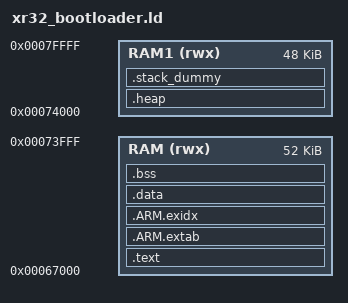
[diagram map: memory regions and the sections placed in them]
/* Linker script to configure memory regions. */
MEMORY
{
	RAM  (rwx) : ORIGIN = 0x00067000, LENGTH = 52K
	RAM1 (rwx) : ORIGIN = 0x00074000, LENGTH = 48K
}

__RAM_BASE = ORIGIN(RAM);

/* Linker script to place sections and symbol values. Should be used together
 * with other linker script that defines memory regions FLASH and RAM.
 * It references following symbols, which must be defined in code:
 *   Reset_Handler : Entry of reset handler
 *
 * It defines following symbols, which code can use without definition:
 *   __exidx_start
 *   __exidx_end
 *   __etext
 *   __data_start__
 *   __preinit_array_start
 *   __preinit_array_end
 *   __init_array_start
 *   __init_array_end
 *   __fini_array_start
 *   __fini_array_end
 *   __data_end__
 *   __bss_start__
 *   __bss_end__
 *   __end__
 *   end
 *   __HeapLimit
 *   __StackLimit
 *   __StackTop
 *   __stack
 *   _estack
 */
ENTRY(Reset_Handler)

SECTIONS
{
	.text :
	{
		. = ALIGN(4);
		__text_start__ = .;

		KEEP(*(.isr_vector))
		KEEP(*(.text.Reset_Handler))
		KEEP(*(.cpu_text))
		*(.text*)
		KEEP(*(.init))
		KEEP(*(.fini))

		/* .ctors */
		*crtbegin.o(.ctors)
		*crtbegin?.o(.ctors)
		*(EXCLUDE_FILE(*crtend?.o *crtend.o) .ctors)
		*(SORT(.ctors.*))
		*(.ctors)

		/* .dtors */
		*crtbegin.o(.dtors)
		*crtbegin?.o(.dtors)
		*(EXCLUDE_FILE(*crtend?.o *crtend.o) .dtors)
		*(SORT(.dtors.*))
		*(.dtors)

		*(.rodata*)

		KEEP(*(.eh_frame*))

		. = ALIGN(4);
		__text_end__ = .;
	} > RAM

	.ARM.extab :
	{
		*(.ARM.extab* .gnu.linkonce.armextab.*)
	} > RAM

	__exidx_start = .;
	.ARM.exidx :
	{
		*(.ARM.exidx* .gnu.linkonce.armexidx.*)
	} > RAM
	__exidx_end = .;

	. = ALIGN(4);
	__etext = .;
	_sidata = .;

	.data :
	{
		. = ALIGN(4);
		__data_start__ = .;
		_sdata = .;

		*(vtable)
		*(.data*)

		. = ALIGN(4);
		/* preinit data */
		PROVIDE_HIDDEN (__preinit_array_start = .);
		KEEP(*(.preinit_array))
		PROVIDE_HIDDEN (__preinit_array_end = .);

		. = ALIGN(4);
		/* init data */
		PROVIDE_HIDDEN (__init_array_start = .);
		KEEP(*(SORT(.init_array.*)))
		KEEP(*(.init_array))
		PROVIDE_HIDDEN (__init_array_end = .);

		. = ALIGN(4);
		/* finit data */
		PROVIDE_HIDDEN (__fini_array_start = .);
		KEEP(*(SORT(.fini_array.*)))
		KEEP(*(.fini_array))
		PROVIDE_HIDDEN (__fini_array_end = .);

		KEEP(*(.jcr*))

		. = ALIGN(4);
		__data_end__ = .;
		_edata = .;
	} > RAM

	.bss :
	{
		. = ALIGN(4);
		__bss_start__ = .;
		_sbss = .;

		*(.bss*)
		*(COMMON)

		. = ALIGN(4);
		__bss_end__ = .;
		_ebss = .;
	} > RAM

	.heap (COPY):
	{
		__end__ = .;
		end = __end__;
		*(.heap*)
		__HeapLimit = .;
	} > RAM1

	/* .stack_dummy section doesn't contains any symbols. It is only
	 * used for linker to calculate size of stack sections, and assign
	 * values to stack symbols later */
	.stack_dummy (COPY):
	{
		*(.stack*)
	} > RAM1

	/* Set stack top to end of RAM1, and stack limit move down by
	 * size of stack_dummy section */
	__StackTop = ORIGIN(RAM1) + LENGTH(RAM1);
	_estack = __StackTop;
	__StackLimit = __StackTop - SIZEOF(.stack_dummy);
	PROVIDE(__stack = __StackTop);

	/* Check if heap + stack exceeds RAM1 limit */
	ASSERT(__StackLimit >= __HeapLimit, "region RAM1 overflowed with stack")
}
